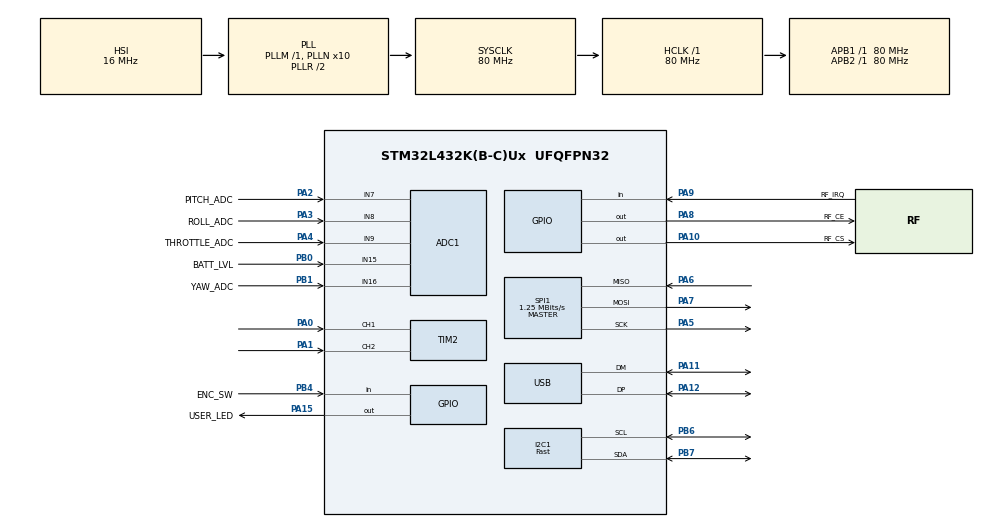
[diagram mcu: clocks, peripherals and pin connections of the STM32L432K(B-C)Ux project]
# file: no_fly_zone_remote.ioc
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ADC1.Channel-0\#ChannelRegularConversion=ADC_CHANNEL_9
ADC1.Channel-1\#ChannelRegularConversion=ADC_CHANNEL_16
ADC1.Channel-2\#ChannelRegularConversion=ADC_CHANNEL_7
ADC1.Channel-3\#ChannelRegularConversion=ADC_CHANNEL_8
ADC1.Channel-4\#ChannelRegularConversion=ADC_CHANNEL_15
ADC1.ContinuousConvMode=DISABLE
ADC1.DMAContinuousRequests=ENABLE
ADC1.EOCSelection=ADC_EOC_SEQ_CONV
ADC1.ExternalTrigConv=ADC_EXTERNALTRIG_T1_TRGO
ADC1.NbrOfConversion=5
ADC1.NbrOfConversionFlag=1
ADC1.OffsetNumber-0\#ChannelRegularConversion=ADC_OFFSET_NONE
ADC1.OffsetNumber-1\#ChannelRegularConversion=ADC_OFFSET_NONE
ADC1.OffsetNumber-2\#ChannelRegularConversion=ADC_OFFSET_NONE
ADC1.OffsetNumber-3\#ChannelRegularConversion=ADC_OFFSET_NONE
ADC1.OffsetNumber-4\#ChannelRegularConversion=ADC_OFFSET_NONE
ADC1.Rank-0\#ChannelRegularConversion=1
ADC1.Rank-1\#ChannelRegularConversion=2
ADC1.Rank-2\#ChannelRegularConversion=3
ADC1.Rank-3\#ChannelRegularConversion=4
ADC1.Rank-4\#ChannelRegularConversion=5
ADC1.SamplingTime-0\#ChannelRegularConversion=ADC_SAMPLETIME_2CYCLES_5
ADC1.SamplingTime-1\#ChannelRegularConversion=ADC_SAMPLETIME_2CYCLES_5
ADC1.SamplingTime-2\#ChannelRegularConversion=ADC_SAMPLETIME_2CYCLES_5
ADC1.SamplingTime-3\#ChannelRegularConversion=ADC_SAMPLETIME_2CYCLES_5
ADC1.SamplingTime-4\#ChannelRegularConversion=ADC_SAMPLETIME_47CYCLES_5
ADC1.master=1
Dma.ADC1.0.Direction=DMA_PERIPH_TO_MEMORY
Dma.ADC1.0.Instance=DMA1_Channel1
Dma.ADC1.0.MemDataAlignment=DMA_MDATAALIGN_HALFWORD
Dma.ADC1.0.MemInc=DMA_MINC_ENABLE
Dma.ADC1.0.Mode=DMA_CIRCULAR
Dma.ADC1.0.PeriphDataAlignment=DMA_PDATAALIGN_HALFWORD
Dma.ADC1.0.PeriphInc=DMA_PINC_DISABLE
Dma.ADC1.0.Priority=DMA_PRIORITY_LOW
Dma.I2C1_TX.1.Direction=DMA_MEMORY_TO_PERIPH
Dma.I2C1_TX.1.Instance=DMA1_Channel6
Dma.I2C1_TX.1.MemDataAlignment=DMA_MDATAALIGN_BYTE
Dma.I2C1_TX.1.MemInc=DMA_MINC_ENABLE
Dma.I2C1_TX.1.Mode=DMA_NORMAL
Dma.I2C1_TX.1.PeriphDataAlignment=DMA_PDATAALIGN_BYTE
Dma.I2C1_TX.1.PeriphInc=DMA_PINC_DISABLE
Dma.I2C1_TX.1.Priority=DMA_PRIORITY_LOW
Dma.Request0=ADC1
Dma.Request1=I2C1_TX
I2C1.I2C_Fall_Time=200
I2C1.I2C_Rise_Time=200
I2C1.I2C_Speed_Mode=I2C_Fast
I2C1.Timing=0x10B51438
Mcu.Family=STM32L4
Mcu.Name=STM32L432K(B-C)Ux
Mcu.Package=UFQFPN32
NVIC.DMA1_Channel1_IRQn=true\:0\:0\:false\:false\:true\:false\:true\:true
NVIC.DMA1_Channel6_IRQn=true\:0\:0\:false\:false\:true\:false\:true\:true
NVIC.I2C1_EV_IRQn=true\:0\:0\:false\:false\:true\:true\:true\:true
NVIC.PriorityGroup=NVIC_PRIORITYGROUP_4
NVIC.TIM6_DAC_IRQn=true\:0\:0\:false\:false\:true\:true\:true\:true
NVIC.USB_IRQn=true\:0\:0\:false\:false\:true\:false\:true\:true
PA0.Signal=S_TIM2_CH1
PA1.Signal=S_TIM2_CH2
PA10.GPIO_Label=RF_CS
PA10.Signal=GPIO_Output
PA11.Mode=Device
PA11.Signal=USB_DM
PA12.Mode=Device
PA12.Signal=USB_DP
PA15\ (JTDI).GPIO_Label=USER_LED
PA15\ (JTDI).Signal=GPIO_Output
PA2.GPIO_Label=PITCH_ADC
PA2.Signal=ADCx_IN7
PA3.GPIO_Label=ROLL_ADC
PA3.Signal=ADCx_IN8
PA4.GPIO_Label=THROTTLE_ADC
PA4.Signal=ADCx_IN9
PA5.Mode=Full_Duplex_Master
PA5.Signal=SPI1_SCK
PA6.Mode=Full_Duplex_Master
PA6.Signal=SPI1_MISO
PA7.Mode=Full_Duplex_Master
PA7.Signal=SPI1_MOSI
PA8.GPIO_Label=RF_CE
PA8.Signal=GPIO_Output
PA9.GPIO_Label=RF_IRQ
PA9.Signal=GPIO_Input
PB0.GPIO_Label=BATT_LVL
PB0.Signal=ADCx_IN15
PB1.GPIO_Label=YAW_ADC
PB1.Signal=ADCx_IN16
PB4\ (NJTRST).GPIO_Label=ENC_SW
PB4\ (NJTRST).Signal=GPIO_Input
PB6.GPIO_Pu=GPIO_NOPULL
PB6.Mode=I2C
PB6.Signal=I2C1_SCL
PB7.GPIO_Pu=GPIO_NOPULL
PB7.Mode=I2C
PB7.Signal=I2C1_SDA
ProjectManager.HeapSize=0x200
ProjectManager.StackSize=0x400
ProjectManager.TargetToolchain=Makefile
RCC.ADCFreq_Value=64000000
RCC.AHBFreq_Value=80000000
RCC.APB1Freq_Value=80000000
RCC.APB1TimFreq_Value=80000000
RCC.APB2Freq_Value=80000000
RCC.APB2TimFreq_Value=80000000
RCC.CK48CLockSelection=RCC_USBCLKSOURCE_HSI48
RCC.CortexFreq_Value=80000000
RCC.HCLKFreq_Value=80000000
RCC.HSE_VALUE=8000000
RCC.HSI48_VALUE=48000000
RCC.HSI_VALUE=16000000
RCC.LSE_VALUE=32768
RCC.MSI_VALUE=4000000
RCC.PLLN=10
RCC.PLLSourceVirtual=RCC_PLLSOURCE_HSI
RCC.SYSCLKFreq_VALUE=80000000
RCC.SYSCLKSource=RCC_SYSCLKSOURCE_PLLCLK
RCC.USBFreq_Value=48000000
RCC.VCOOutputFreq_Value=160000000
SH.ADCx_IN15.0=ADC1_IN15,IN15-Single-Ended
SH.ADCx_IN16.0=ADC1_IN16,IN16-Single-Ended
SH.ADCx_IN7.0=ADC1_IN7,IN7-Single-Ended
SH.ADCx_IN8.0=ADC1_IN8,IN8-Single-Ended
SH.ADCx_IN9.0=ADC1_IN9,IN9-Single-Ended
SH.S_TIM2_CH1.0=TIM2_CH1,Encoder_Interface
SH.S_TIM2_CH2.0=TIM2_CH2,Encoder_Interface
SPI1.BaudRatePrescaler=SPI_BAUDRATEPRESCALER_64
SPI1.CalculateBaudRate=1.25 MBits/s
SPI1.DataSize=SPI_DATASIZE_8BIT
SPI1.Direction=SPI_DIRECTION_2LINES
SPI1.Mode=SPI_MODE_MASTER
SPI1.VirtualType=VM_MASTER
TIM1.ClockDivision=TIM_CLOCKDIVISION_DIV1
TIM1.Period=6249
TIM1.Prescaler=63
TIM1.TIM_MasterOutputTrigger=TIM_TRGO_UPDATE
TIM2.AutoReloadPreload=TIM_AUTORELOAD_PRELOAD_DISABLE
TIM6.Prescaler=79
USB_DEVICE.CLASS_NAME_FS=CDC
USB_DEVICE.VirtualMode=Cdc
USB_DEVICE.VirtualModeFS=Cdc_FS
VP_IWDG_VS_IWDG.Mode=IWDG_Activate
VP_TIM1_VS_ClockSourceINT.Mode=Internal
VP_TIM6_VS_ClockSourceINT.Mode=Enable_Timer
VP_USB_DEVICE_VS_USB_DEVICE_CDC_FS.Mode=CDC_FS
board=custom

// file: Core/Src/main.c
/* USER CODE BEGIN Header */
/**
 ******************************************************************************
 * @file           : main.c
 * @brief          : Main program body
 ******************************************************************************
 * @attention
 *
 * Copyright (c) 2026 STMicroelectronics.
 * All rights reserved.
 *
 * This software is licensed under terms that can be found in the LICENSE file
 * in the root directory of this software component.
 * If no LICENSE file comes with this software, it is provided AS-IS.
 *
 ******************************************************************************
 */
/* USER CODE END Header */
#include "main.h"
#include "usb_device.h"

/* USER CODE BEGIN Includes */
#include "app.h"
/* USER CODE END Includes */

ADC_HandleTypeDef hadc1;
DMA_HandleTypeDef hdma_adc1;

I2C_HandleTypeDef hi2c1;
DMA_HandleTypeDef hdma_i2c1_tx;

IWDG_HandleTypeDef hiwdg;

SPI_HandleTypeDef hspi1;

TIM_HandleTypeDef htim1;
TIM_HandleTypeDef htim2;
TIM_HandleTypeDef htim6;

void SystemClock_Config(void);
static void MX_GPIO_Init(void);
static void MX_DMA_Init(void);
static void MX_ADC1_Init(void);
static void MX_I2C1_Init(void);
static void MX_SPI1_Init(void);
static void MX_TIM1_Init(void);
static void MX_TIM2_Init(void);
static void MX_TIM6_Init(void);
static void MX_IWDG_Init(void);

int main(void)
{

    /* MCU Configuration--------------------------------------------------------*/

    /* Reset of all peripherals, Initializes the Flash interface and the Systick. */
    HAL_Init();

    /* Configure the system clock */
    SystemClock_Config();

    /* Initialize all configured peripherals */
    MX_GPIO_Init();
    MX_DMA_Init();
    MX_ADC1_Init();
    MX_I2C1_Init();
    MX_SPI1_Init();
    MX_TIM1_Init();
    MX_TIM2_Init();
    MX_USB_DEVICE_Init();
    MX_TIM6_Init();
    MX_IWDG_Init();
    /* USER CODE BEGIN 2 */
    app_init(&hadc1, &hdma_adc1, &hi2c1, &hspi1, &htim1, &htim2, &htim6, &hiwdg);
    /* USER CODE END 2 */

    /* Infinite loop */
    /* USER CODE BEGIN WHILE */
    while (1)
    {
        app();
        /* USER CODE END WHILE */

    }
}

void SystemClock_Config(void)
{
    RCC_OscInitTypeDef RCC_OscInitStruct = { 0 };
    RCC_ClkInitTypeDef RCC_ClkInitStruct = { 0 };

    /** Configure the main internal regulator output voltage
  */
    if (HAL_PWREx_ControlVoltageScaling(PWR_REGULATOR_VOLTAGE_SCALE1) != HAL_OK)
    {
        Error_Handler();
    }

    /** Initializes the RCC Oscillators according to the specified parameters
  * in the RCC_OscInitTypeDef structure.
  */
    RCC_OscInitStruct.OscillatorType = RCC_OSCILLATORTYPE_HSI48 | RCC_OSCILLATORTYPE_HSI | RCC_OSCILLATORTYPE_LSI;
    RCC_OscInitStruct.HSIState = RCC_HSI_ON;
    RCC_OscInitStruct.HSI48State = RCC_HSI48_ON;
    RCC_OscInitStruct.HSICalibrationValue = RCC_HSICALIBRATION_DEFAULT;
    RCC_OscInitStruct.LSIState = RCC_LSI_ON;
    RCC_OscInitStruct.PLL.PLLState = RCC_PLL_ON;
    RCC_OscInitStruct.PLL.PLLSource = RCC_PLLSOURCE_HSI;
    RCC_OscInitStruct.PLL.PLLM = 1;
    RCC_OscInitStruct.PLL.PLLN = 10;
    RCC_OscInitStruct.PLL.PLLP = RCC_PLLP_DIV7;
    RCC_OscInitStruct.PLL.PLLQ = RCC_PLLQ_DIV2;
    RCC_OscInitStruct.PLL.PLLR = RCC_PLLR_DIV2;
    if (HAL_RCC_OscConfig(&RCC_OscInitStruct) != HAL_OK)
    {
        Error_Handler();
    }

    /** Initializes the CPU, AHB and APB buses clocks
  */
    RCC_ClkInitStruct.ClockType = RCC_CLOCKTYPE_HCLK | RCC_CLOCKTYPE_SYSCLK | RCC_CLOCKTYPE_PCLK1 | RCC_CLOCKTYPE_PCLK2;
    RCC_ClkInitStruct.SYSCLKSource = RCC_SYSCLKSOURCE_PLLCLK;
    RCC_ClkInitStruct.AHBCLKDivider = RCC_SYSCLK_DIV1;
    RCC_ClkInitStruct.APB1CLKDivider = RCC_HCLK_DIV1;
    RCC_ClkInitStruct.APB2CLKDivider = RCC_HCLK_DIV1;

    if (HAL_RCC_ClockConfig(&RCC_ClkInitStruct, FLASH_LATENCY_4) != HAL_OK)
    {
        Error_Handler();
    }
}

static void MX_ADC1_Init(void)
{

    ADC_ChannelConfTypeDef sConfig = { 0 };

    /** Common config
  */
    hadc1.Instance = ADC1;
    hadc1.Init.ClockPrescaler = ADC_CLOCK_ASYNC_DIV1;
    hadc1.Init.Resolution = ADC_RESOLUTION_12B;
    hadc1.Init.DataAlign = ADC_DATAALIGN_RIGHT;
    hadc1.Init.ScanConvMode = ADC_SCAN_ENABLE;
    hadc1.Init.EOCSelection = ADC_EOC_SEQ_CONV;
    hadc1.Init.LowPowerAutoWait = DISABLE;
    hadc1.Init.ContinuousConvMode = DISABLE;
    hadc1.Init.NbrOfConversion = 5;
    hadc1.Init.DiscontinuousConvMode = DISABLE;
    hadc1.Init.ExternalTrigConv = ADC_EXTERNALTRIG_T1_TRGO;
    hadc1.Init.ExternalTrigConvEdge = ADC_EXTERNALTRIGCONVEDGE_RISING;
    hadc1.Init.DMAContinuousRequests = ENABLE;
    hadc1.Init.Overrun = ADC_OVR_DATA_PRESERVED;
    hadc1.Init.OversamplingMode = DISABLE;
    if (HAL_ADC_Init(&hadc1) != HAL_OK)
    {
        Error_Handler();
    }

    /** Configure Regular Channel
  */
    sConfig.Channel = ADC_CHANNEL_9;
    sConfig.Rank = ADC_REGULAR_RANK_1;
    sConfig.SamplingTime = ADC_SAMPLETIME_2CYCLES_5;
    sConfig.SingleDiff = ADC_SINGLE_ENDED;
    sConfig.OffsetNumber = ADC_OFFSET_NONE;
    sConfig.Offset = 0;
    if (HAL_ADC_ConfigChannel(&hadc1, &sConfig) != HAL_OK)
    {
        Error_Handler();
    }

    /** Configure Regular Channel
  */
    sConfig.Channel = ADC_CHANNEL_16;
    sConfig.Rank = ADC_REGULAR_RANK_2;
    if (HAL_ADC_ConfigChannel(&hadc1, &sConfig) != HAL_OK)
    {
        Error_Handler();
    }

    /** Configure Regular Channel
  */
    sConfig.Channel = ADC_CHANNEL_7;
    sConfig.Rank = ADC_REGULAR_RANK_3;
    if (HAL_ADC_ConfigChannel(&hadc1, &sConfig) != HAL_OK)
    {
        Error_Handler();
    }

    /** Configure Regular Channel
  */
    sConfig.Channel = ADC_CHANNEL_8;
    sConfig.Rank = ADC_REGULAR_RANK_4;
    if (HAL_ADC_ConfigChannel(&hadc1, &sConfig) != HAL_OK)
    {
        Error_Handler();
    }

    /** Configure Regular Channel
  */
    sConfig.Channel = ADC_CHANNEL_15;
    sConfig.Rank = ADC_REGULAR_RANK_5;
    sConfig.SamplingTime = ADC_SAMPLETIME_47CYCLES_5;
    if (HAL_ADC_ConfigChannel(&hadc1, &sConfig) != HAL_OK)
    {
        Error_Handler();
    }
}

static void MX_I2C1_Init(void)
{

    hi2c1.Instance = I2C1;
    hi2c1.Init.Timing = 0x10B51438;
    hi2c1.Init.OwnAddress1 = 0;
    hi2c1.Init.AddressingMode = I2C_ADDRESSINGMODE_7BIT;
    hi2c1.Init.DualAddressMode = I2C_DUALADDRESS_DISABLE;
    hi2c1.Init.OwnAddress2 = 0;
    hi2c1.Init.OwnAddress2Masks = I2C_OA2_NOMASK;
    hi2c1.Init.GeneralCallMode = I2C_GENERALCALL_DISABLE;
    hi2c1.Init.NoStretchMode = I2C_NOSTRETCH_DISABLE;
    if (HAL_I2C_Init(&hi2c1) != HAL_OK)
    {
        Error_Handler();
    }

    /** Configure Analogue filter
  */
    if (HAL_I2CEx_ConfigAnalogFilter(&hi2c1, I2C_ANALOGFILTER_ENABLE) != HAL_OK)
    {
        Error_Handler();
    }

    /** Configure Digital filter
  */
    if (HAL_I2CEx_ConfigDigitalFilter(&hi2c1, 0) != HAL_OK)
    {
        Error_Handler();
    }
}

static void MX_IWDG_Init(void)
{

    hiwdg.Instance = IWDG;
    hiwdg.Init.Prescaler = IWDG_PRESCALER_4;
    hiwdg.Init.Window = 4095;
    hiwdg.Init.Reload = 4095;
    if (HAL_IWDG_Init(&hiwdg) != HAL_OK)
    {
        Error_Handler();
    }
}

static void MX_SPI1_Init(void)
{

    /* SPI1 parameter configuration*/
    hspi1.Instance = SPI1;
    hspi1.Init.Mode = SPI_MODE_MASTER;
    hspi1.Init.Direction = SPI_DIRECTION_2LINES;
    hspi1.Init.DataSize = SPI_DATASIZE_8BIT;
    hspi1.Init.CLKPolarity = SPI_POLARITY_LOW;
    hspi1.Init.CLKPhase = SPI_PHASE_1EDGE;
    hspi1.Init.NSS = SPI_NSS_SOFT;
    hspi1.Init.BaudRatePrescaler = SPI_BAUDRATEPRESCALER_64;
    hspi1.Init.FirstBit = SPI_FIRSTBIT_MSB;
    hspi1.Init.TIMode = SPI_TIMODE_DISABLE;
    hspi1.Init.CRCCalculation = SPI_CRCCALCULATION_DISABLE;
    hspi1.Init.CRCPolynomial = 7;
    hspi1.Init.CRCLength = SPI_CRC_LENGTH_DATASIZE;
    hspi1.Init.NSSPMode = SPI_NSS_PULSE_ENABLE;
    if (HAL_SPI_Init(&hspi1) != HAL_OK)
    {
        Error_Handler();
    }
}

static void MX_TIM1_Init(void)
{

    TIM_ClockConfigTypeDef sClockSourceConfig = { 0 };
    TIM_MasterConfigTypeDef sMasterConfig = { 0 };

    htim1.Instance = TIM1;
    htim1.Init.Prescaler = 63;
    htim1.Init.CounterMode = TIM_COUNTERMODE_UP;
    htim1.Init.Period = 6249;
    htim1.Init.ClockDivision = TIM_CLOCKDIVISION_DIV1;
    htim1.Init.RepetitionCounter = 0;
    htim1.Init.AutoReloadPreload = TIM_AUTORELOAD_PRELOAD_DISABLE;
    if (HAL_TIM_Base_Init(&htim1) != HAL_OK)
    {
        Error_Handler();
    }
    sClockSourceConfig.ClockSource = TIM_CLOCKSOURCE_INTERNAL;
    if (HAL_TIM_ConfigClockSource(&htim1, &sClockSourceConfig) != HAL_OK)
    {
        Error_Handler();
    }
    sMasterConfig.MasterOutputTrigger = TIM_TRGO_UPDATE;
    sMasterConfig.MasterOutputTrigger2 = TIM_TRGO2_RESET;
    sMasterConfig.MasterSlaveMode = TIM_MASTERSLAVEMODE_DISABLE;
    if (HAL_TIMEx_MasterConfigSynchronization(&htim1, &sMasterConfig) != HAL_OK)
    {
        Error_Handler();
    }
}

static void MX_TIM2_Init(void)
{

    TIM_Encoder_InitTypeDef sConfig = { 0 };
    TIM_MasterConfigTypeDef sMasterConfig = { 0 };

    htim2.Instance = TIM2;
    htim2.Init.Prescaler = 0;
    htim2.Init.CounterMode = TIM_COUNTERMODE_UP;
    htim2.Init.Period = 4294967295;
    htim2.Init.ClockDivision = TIM_CLOCKDIVISION_DIV1;
    htim2.Init.AutoReloadPreload = TIM_AUTORELOAD_PRELOAD_DISABLE;
    sConfig.EncoderMode = TIM_ENCODERMODE_TI1;
    sConfig.IC1Polarity = TIM_ICPOLARITY_RISING;
    sConfig.IC1Selection = TIM_ICSELECTION_DIRECTTI;
    sConfig.IC1Prescaler = TIM_ICPSC_DIV1;
    sConfig.IC1Filter = 0;
    sConfig.IC2Polarity = TIM_ICPOLARITY_RISING;
    sConfig.IC2Selection = TIM_ICSELECTION_DIRECTTI;
    sConfig.IC2Prescaler = TIM_ICPSC_DIV1;
    sConfig.IC2Filter = 0;
    if (HAL_TIM_Encoder_Init(&htim2, &sConfig) != HAL_OK)
    {
        Error_Handler();
    }
    sMasterConfig.MasterOutputTrigger = TIM_TRGO_RESET;
    sMasterConfig.MasterSlaveMode = TIM_MASTERSLAVEMODE_DISABLE;
    if (HAL_TIMEx_MasterConfigSynchronization(&htim2, &sMasterConfig) != HAL_OK)
    {
        Error_Handler();
    }
}

static void MX_TIM6_Init(void)
{

    TIM_MasterConfigTypeDef sMasterConfig = { 0 };

    htim6.Instance = TIM6;
    htim6.Init.Prescaler = 79;
    htim6.Init.CounterMode = TIM_COUNTERMODE_UP;
    htim6.Init.Period = 65535;
    htim6.Init.AutoReloadPreload = TIM_AUTORELOAD_PRELOAD_DISABLE;
    if (HAL_TIM_Base_Init(&htim6) != HAL_OK)
    {
        Error_Handler();
    }
    sMasterConfig.MasterOutputTrigger = TIM_TRGO_RESET;
    sMasterConfig.MasterSlaveMode = TIM_MASTERSLAVEMODE_DISABLE;
    if (HAL_TIMEx_MasterConfigSynchronization(&htim6, &sMasterConfig) != HAL_OK)
    {
        Error_Handler();
    }
}

static void MX_DMA_Init(void)
{

    /* DMA controller clock enable */
    __HAL_RCC_DMA1_CLK_ENABLE();

    /* DMA interrupt init */
    /* DMA1_Channel1_IRQn interrupt configuration */
    HAL_NVIC_SetPriority(DMA1_Channel1_IRQn, 0, 0);
    HAL_NVIC_EnableIRQ(DMA1_Channel1_IRQn);
    /* DMA1_Channel6_IRQn interrupt configuration */
    HAL_NVIC_SetPriority(DMA1_Channel6_IRQn, 0, 0);
    HAL_NVIC_EnableIRQ(DMA1_Channel6_IRQn);
}

static void MX_GPIO_Init(void)
{
    GPIO_InitTypeDef GPIO_InitStruct = { 0 };

    /* GPIO Ports Clock Enable */
    __HAL_RCC_GPIOA_CLK_ENABLE();
    __HAL_RCC_GPIOB_CLK_ENABLE();

    /*Configure GPIO pin Output Level */
    HAL_GPIO_WritePin(GPIOA, RF_CE_Pin | RF_CS_Pin | USER_LED_Pin, GPIO_PIN_RESET);

    /*Configure GPIO pins : RF_CE_Pin RF_CS_Pin USER_LED_Pin */
    GPIO_InitStruct.Pin = RF_CE_Pin | RF_CS_Pin | USER_LED_Pin;
    GPIO_InitStruct.Mode = GPIO_MODE_OUTPUT_PP;
    GPIO_InitStruct.Pull = GPIO_NOPULL;
    GPIO_InitStruct.Speed = GPIO_SPEED_FREQ_LOW;
    HAL_GPIO_Init(GPIOA, &GPIO_InitStruct);

    /*Configure GPIO pin : RF_IRQ_Pin */
    GPIO_InitStruct.Pin = RF_IRQ_Pin;
    GPIO_InitStruct.Mode = GPIO_MODE_INPUT;
    GPIO_InitStruct.Pull = GPIO_NOPULL;
    HAL_GPIO_Init(RF_IRQ_GPIO_Port, &GPIO_InitStruct);

    /*Configure GPIO pin : ENC_SW_Pin */
    GPIO_InitStruct.Pin = ENC_SW_Pin;
    GPIO_InitStruct.Mode = GPIO_MODE_INPUT;
    GPIO_InitStruct.Pull = GPIO_NOPULL;
    HAL_GPIO_Init(ENC_SW_GPIO_Port, &GPIO_InitStruct);

}

void Error_Handler(void)
{
    __disable_irq();
    while (1)
    {
    }
}
